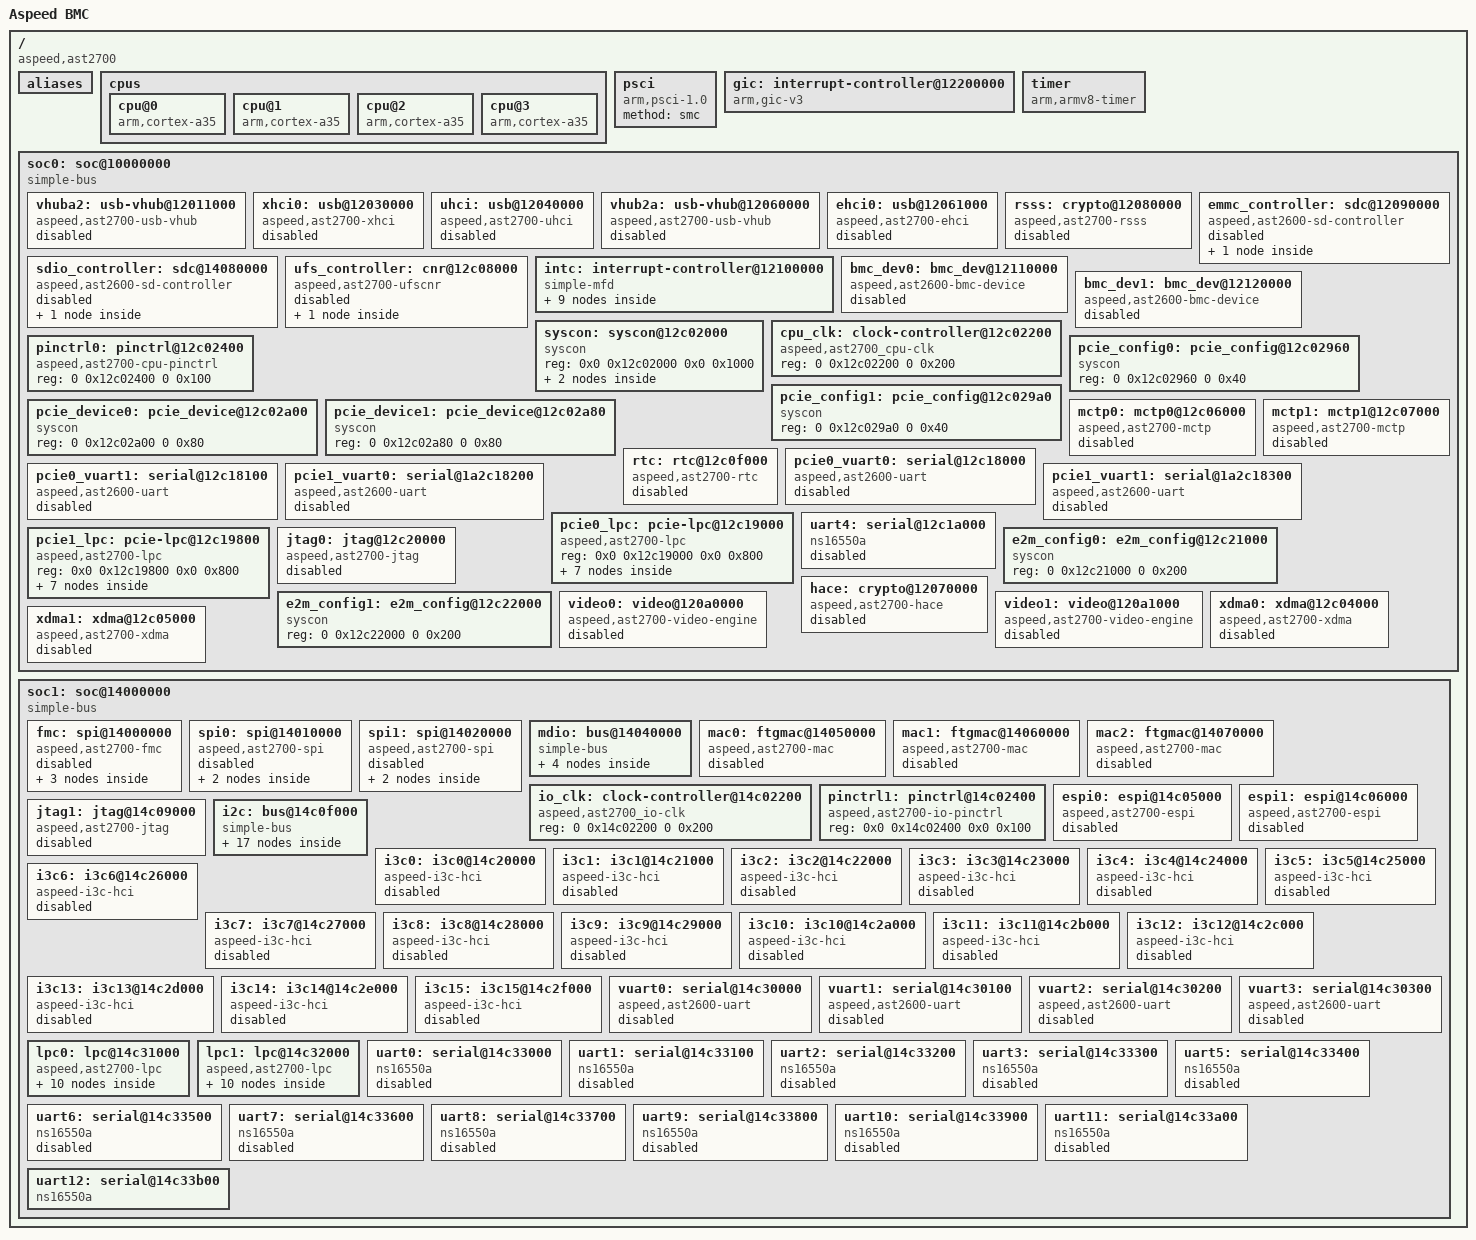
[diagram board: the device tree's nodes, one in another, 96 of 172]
// SPDX-License-Identifier: GPL-2.0-or-later
#include <dt-bindings/clock/aspeed,ast2700-clk.h>
#include <dt-bindings/reset/aspeed,ast2700-reset.h>
#include <dt-bindings/interrupt-controller/arm-gic.h>
#include <dt-bindings/interrupt-controller/aspeed-scu-ic.h>

/ {
	model = "Aspeed BMC";
	compatible = "aspeed,ast2700";
	#address-cells = <2>;
	#size-cells = <2>;
	interrupt-parent = <&gic>;

	aliases {
		serial0 = &uart0;
		serial1 = &uart1;
		serial2 = &uart2;
		serial3 = &uart3;
		serial4 = &uart4;
		serial5 = &uart5;
		serial6 = &uart6;
		serial7 = &uart7;
		serial8 = &uart8;
		serial9 = &uart9;
		serial10 = &uart10;
		serial11 = &uart11;
		serial12 = &uart12;
		serial13 = &vuart0;
		serial14 = &vuart1;
		serial15 = &vuart2;
		serial16 = &vuart3;
		serial17 = &pcie0_vuart0;
		serial18 = &pcie0_vuart1;
		serial19 = &pcie1_vuart0;
		serial20 = &pcie1_vuart1;
		i2c0 = &i2c0;
		i2c1 = &i2c1;
		i2c2 = &i2c2;
		i2c3 = &i2c3;
		i2c4 = &i2c4;
		i2c5 = &i2c5;
		i2c6 = &i2c6;
		i2c7 = &i2c7;
		i2c8 = &i2c8;
		i2c9 = &i2c9;
		i2c10 = &i2c10;
		i2c11 = &i2c11;
		i2c12 = &i2c12;
		i2c13 = &i2c13;
		i2c14 = &i2c14;
		i2c15 = &i2c15;
		mdio0 = &mdio0;
		mdio1 = &mdio1;
		mdio2 = &mdio2;
		mdio3 = &mdio3;
		video0 = &video0;
		video1 = &video1;
	};

	cpus {
		#address-cells = <1>;
		#size-cells = <0>;

		cpu@0 {
			compatible = "arm,cortex-a35";
			enable-method = "psci";
			device_type = "cpu";
			reg = <0>;
		};

		cpu@1 {
			compatible = "arm,cortex-a35";
			enable-method = "psci";
			device_type = "cpu";
			reg = <1>;
		};

		cpu@2 {
			compatible = "arm,cortex-a35";
			enable-method = "psci";
			device_type = "cpu";
			reg = <2>;
		};

		cpu@3 {
			compatible = "arm,cortex-a35";
			enable-method = "psci";
			device_type = "cpu";
			reg = <3>;
		};
	};

	psci {
		compatible = "arm,psci-1.0";
		method = "smc";
	};

	gic: interrupt-controller@12200000 {
		compatible = "arm,gic-v3";
		interrupts = <GIC_PPI 9 (GIC_CPU_MASK_SIMPLE(2) | IRQ_TYPE_LEVEL_HIGH)>;
		#interrupt-cells = <3>;
		interrupt-controller;
		interrupt-parent = <&gic>;
		#redistributor-regions = <1>;
		reg =	<0 0x12200000 0 0x10000>,		//GICD
			<0 0x12280000 0 0x80000>,		//GICR
			<0 0x40440000 0 0x1000>;		//GICC
	};

	timer {
		compatible = "arm,armv8-timer";
		interrupt-parent = <&gic>;
		interrupts = <GIC_PPI 13 (GIC_CPU_MASK_SIMPLE(2) | IRQ_TYPE_LEVEL_LOW)>,
				<GIC_PPI 14 (GIC_CPU_MASK_SIMPLE(2) | IRQ_TYPE_LEVEL_LOW)>,
				<GIC_PPI 11 (GIC_CPU_MASK_SIMPLE(2) | IRQ_TYPE_LEVEL_LOW)>,
				<GIC_PPI 10 (GIC_CPU_MASK_SIMPLE(2) | IRQ_TYPE_LEVEL_LOW)>;
		arm,cpu-registers-not-fw-configured;
		always-on;
	};

	soc0: soc@10000000 {
		compatible = "simple-bus";
		#address-cells = <2>;
		#size-cells = <2>;
		ranges;

		vhuba2: usb-vhub@12011000 {
			compatible = "aspeed,ast2700-usb-vhub";
			reg = <0x0 0x12011000 0x0 0x350>;
			interrupts = <GIC_SPI 32 IRQ_TYPE_LEVEL_HIGH>;
			clocks = <&cpu_clk AST2700_CPU_CLK_GATE_USB0CLK>;
			aspeed,vhub-downstream-ports = <7>;
			aspeed,vhub-generic-endpoints = <21>;
			status = "disabled";
		};

		xhci0: usb@12030000 {
			compatible = "aspeed,ast2700-xhci", "snps,dwc3";
			reg = <0x0 0x12030000 0x0 0x10000>;
			interrupts = <GIC_SPI 30 IRQ_TYPE_LEVEL_HIGH>;
			status = "disabled";
		};

		uhci: usb@12040000 {
			compatible = "aspeed,ast2700-uhci", "generic-uhci";
			reg = <0x0 0x12040000 0x0 0x100>;
			interrupts = <GIC_SPI 10 IRQ_TYPE_LEVEL_HIGH>;
			#ports = <2>;
			clocks = <&cpu_clk AST2700_CPU_CLK_GATE_USB0CLK>;
			status = "disabled";
		};

		vhub2a: usb-vhub@12060000 {
			compatible = "aspeed,ast2700-usb-vhub";
			reg = <0x0 0x12060000 0x0 0x350>;
			interrupts = <GIC_SPI 33 IRQ_TYPE_LEVEL_HIGH>;
			clocks = <&cpu_clk AST2700_CPU_CLK_GATE_USB0CLK>;
			aspeed,vhub-downstream-ports = <7>;
			aspeed,vhub-generic-endpoints = <21>;
			status = "disabled";
		};

		ehci0: usb@12061000 {
			compatible = "aspeed,ast2700-ehci", "generic-ehci";
			reg = <0x0 0x12061000 0x0 0x100>;
			interrupts = <GIC_SPI 33 IRQ_TYPE_LEVEL_HIGH>;
			clocks = <&cpu_clk AST2700_CPU_CLK_GATE_USB0CLK>;
			status = "disabled";
		};

		rsss: crypto@12080000 {
			compatible = "aspeed,ast2700-rsss";
			reg = <0x0 0x12080000 0 0x1000>;
			clocks = <&cpu_clk AST2700_CPU_CLK_GATE_RSACLK>;
			interrupts = <GIC_SPI 3 IRQ_TYPE_LEVEL_HIGH>;
			resets = <&cpu_clk ASPEED_RESET_RSA>,
				 <&cpu_clk ASPEED_RESET_SHA3>,
				 <&cpu_clk ASPEED_RESET_SM3>,
				 <&cpu_clk ASPEED_RESET_SM4>;
			status = "disabled";
		};

		emmc_controller: sdc@12090000 {
			compatible = "aspeed,ast2600-sd-controller";
			reg = <0 0x12090000 0 0x100>;
			#address-cells = <2>;
			#size-cells = <2>;
			ranges = <0 0 0 0x12090000 0 0x10000>;
			clocks = <&cpu_clk AST2700_CPU_CLK_GATE_EMMCCLK>;
			resets = <&cpu_clk ASPEED_RESET_EMMC>;
			status = "disable";

			emmc: sdhci@12090100 {
				compatible = "aspeed,ast2600-emmc";
				reg = <0 0x100 0 0x100>;
				sdhci,auto-cmd12;
				interrupts = <GIC_SPI 15 IRQ_TYPE_LEVEL_HIGH>;
				clocks = <&cpu_clk AST2700_CPU_CLK_GATE_EMMCCLK>;
				pinctrl-names = "default";
				pinctrl-0 = <&pinctrl_emmc_default>;
				status = "disable";
			};
		};

		sdio_controller: sdc@14080000 {
			compatible = "aspeed,ast2600-sd-controller";
			reg = <0 0x14080000 0 0x100>;
			#address-cells = <2>;
			#size-cells = <2>;
			ranges = <0 0 0 0x14080000 0 0x10000>;
			clocks = <&io_clk AST2700_IO_CLK_GATE_SDCLK>;
			resets = <&io_clk ASPEED_RESET_SD>;
			status = "disable";

			sdhci: sdhci@14080100 {
				compatible = "aspeed,ast2600-sdhci", "sdhci";
				reg = <0 0x100 0 0x100>;
				sdhci,auto-cmd12;
				interrupt-parent = <&intc5>;
				interrupts-extended = <&intc5 1>;
				clocks = <&io_clk AST2700_IO_CLK_GATE_SDCLK>;
				pinctrl-names = "default";
				pinctrl-0 = <&pinctrl_sd_default>;
				status = "disable";
			};
		};

		ufs_controller: cnr@12c08000 {
			compatible = "aspeed,ast2700-ufscnr";
			reg = <0 0x12c08000 0 0x100>;
			#address-cells = <2>;
			#size-cells = <2>;
			ranges = <0 0 0 0x12c08000 0 0x300>;
			clocks = <&cpu_clk AST2700_CPU_CLK_GATE_UFSCLK>;
			resets = <&cpu_clk ASPEED_RESET_UFS>;
			status = "disable";

			ufs: ufshc@12c08200 {
				compatible = "aspeed,ast2700-ufshc";
				reg = <0 0x200 0 0x100>;
				interrupts = <GIC_SPI 118 IRQ_TYPE_LEVEL_HIGH>;
				status = "disable";
			};
		};

		intc: interrupt-controller@12100000 {
			compatible = "simple-mfd";
			#address-cells = <2>;
			#size-cells = <2>;
			ranges = <0x0 0x0 0x0 0x12100000 0x0 0x4000>;

			intc0: interrupt-controller@1000 {
				#interrupt-cells = <1>;
				interrupt-controller;
				compatible = "aspeed,ast2700-intc-ic";
				reg = <0x0 0x1000 0x0 0x10>;
				interrupts = <GIC_SPI 128 IRQ_TYPE_LEVEL_HIGH>;
			};

			intc1: interrupt-controller@1100 {
				#interrupt-cells = <1>;
				interrupt-controller;
				compatible = "aspeed,ast2700-intc-ic";
				reg = <0x0 0x1100 0x0 0x10>;
				interrupts = <GIC_SPI 129 IRQ_TYPE_LEVEL_HIGH>;
			};

			intc2: interrupt-controller@1200 {
				#interrupt-cells = <1>;
				interrupt-controller;
				compatible = "aspeed,ast2700-intc-ic";
				reg = <0x0 0x1200 0x0 0x10>;
				interrupts = <GIC_SPI 130 IRQ_TYPE_LEVEL_HIGH>;
			};

			intc3: interrupt-controller@1300 {
				#interrupt-cells = <1>;
				interrupt-controller;
				compatible = "aspeed,ast2700-intc-ic";
				reg = <0x0 0x1300 0x0 0x10>;
				interrupts = <GIC_SPI 131 IRQ_TYPE_LEVEL_HIGH>;
			};

			intc4: interrupt-controller@1400 {
				#interrupt-cells = <1>;
				interrupt-controller;
				compatible = "aspeed,ast2700-intc-ic";
				reg = <0x0 0x1400 0x0 0x10>;
				interrupts = <GIC_SPI 132 IRQ_TYPE_LEVEL_HIGH>;
			};

			intc5: interrupt-controller@1500 {
				#interrupt-cells = <1>;
				interrupt-controller;
				compatible = "aspeed,ast2700-intc-ic";
				reg = <0x0 0x1500 0x0 0x10>;
				interrupts = <GIC_SPI 133 IRQ_TYPE_LEVEL_HIGH>;
			};

			intc6: interrupt-controller@1600 {
				#interrupt-cells = <1>;
				interrupt-controller;
				compatible = "aspeed,ast2700-intc-ic";
				reg = <0x0 0x1600 0x0 0x10>;
				interrupts = <GIC_SPI 134 IRQ_TYPE_LEVEL_HIGH>;
			};

			intc7: interrupt-controller@1700 {
				#interrupt-cells = <1>;
				interrupt-controller;
				compatible = "aspeed,ast2700-intc-ic";
				reg = <0x0 0x1700 0x0 0x10>;
				interrupts = <GIC_SPI 135 IRQ_TYPE_LEVEL_HIGH>;
			};

			intc8: interrupt-controller@1800 {
				#interrupt-cells = <1>;
				interrupt-controller;
				compatible = "aspeed,ast2700-intc-ic";
				reg = <0x0 0x12101800 0x0 0x10>;
				interrupts = <GIC_SPI 136 IRQ_TYPE_LEVEL_HIGH>;
			};
		};

		bmc_dev0: bmc_dev@12110000 {
			compatible = "aspeed,ast2600-bmc-device";
			reg = <0x0 0x12110000 0x0 0xb000>;
			interrupts = <GIC_SPI 42 IRQ_TYPE_LEVEL_HIGH>;
			aspeed,config = <&pcie_config0>;
			aspeed,device = <&pcie_device0>;
			aspeed,e2m = <&e2m_config0>;
			pcie2lpc;
			status = "disabled";
		};

		bmc_dev1: bmc_dev@12120000 {
			compatible = "aspeed,ast2600-bmc-device";
			reg = <0x0 0x12120000 0x0 0xb000>;
			interrupts = <GIC_SPI 43 IRQ_TYPE_LEVEL_HIGH>;
			aspeed,config = <&pcie_config1>;
			aspeed,device = <&pcie_device1>;
			aspeed,e2m = <&e2m_config1>;
			pcie2lpc;
			status = "disabled";
		};

		syscon: syscon@12c02000 {
			compatible = "syscon", "simple-mfd";
			reg = <0x0 0x12c02000 0x0 0x1000>;
			ranges = <0x0 0x0 0x12c02000 0x1000>;
			#address-cells = <1>;
			#size-cells = <1>;
			#clock-cells = <1>;
			#reset-cells = <1>;

			scu_ic0: interrupt-controller@1D0 {
				#interrupt-cells = <1>;
				compatible = "aspeed,ast2700-scu-ic0";
				reg = <0x1D0 0xc>;
				interrupts = <GIC_SPI 97 IRQ_TYPE_LEVEL_HIGH>;
				interrupt-controller;
			};

			scu_ic1: interrupt-controller@1E0 {
				#interrupt-cells = <1>;
				compatible = "aspeed,ast2700-scu-ic1";
				reg = <0x1E0 0xc>;
				interrupts = <GIC_SPI 98 IRQ_TYPE_LEVEL_HIGH>;
				interrupt-controller;
			};
		};

		cpu_clk: clock-controller@12c02200 {
			compatible = "aspeed,ast2700_cpu-clk";
			reg = <0 0x12c02200 0 0x200>;
			#clock-cells = <1>;
			#reset-cells = <1>;
		};

		pinctrl0: pinctrl@12c02400 {
			compatible = "aspeed,ast2700-cpu-pinctrl";
			reg = <0 0x12c02400 0 0x100>;
		};

		pcie_config0: pcie_config@12c02960 {
			compatible = "syscon", "simple-mfd";
			reg = <0 0x12c02960 0 0x40>;
		};

		pcie_config1: pcie_config@12c029a0 {
			compatible = "syscon", "simple-mfd";
			reg = <0 0x12c029a0 0 0x40>;
		};

		pcie_device0: pcie_device@12c02a00 {
			compatible = "syscon", "simple-mfd";
			reg = <0 0x12c02a00 0 0x80>;
		};

		pcie_device1: pcie_device@12c02a80 {
			compatible = "syscon", "simple-mfd";
			reg = <0 0x12c02a80 0 0x80>;
		};

		mctp0: mctp0@12c06000 {
			compatible = "aspeed,ast2700-mctp";
			reg = <0x0 0x12c06000 0x0 0x40>;
			interrupts-extended = <&gic GIC_SPI 24 IRQ_TYPE_LEVEL_HIGH>, <&scu_ic0 ASPEED_AST2700_SCU_IC0_PCIE_PERST_LO_TO_HI>;
			interrupt-names = "mctp", "pcie";
			resets = <&cpu_clk ASPEED_RESET_MCTP0>;
			aspeed,scu = <&syscon>;
			aspeed,pcieh = <&pcie_config0>;
			status = "disabled";
		};

		mctp1: mctp1@12c07000 {
			compatible = "aspeed,ast2700-mctp";
			reg = <0x0 0x12c07000 0x0 0x40>;
			interrupts-extended = <&gic GIC_SPI 25 IRQ_TYPE_LEVEL_HIGH>, <&scu_ic1 ASPEED_AST2700_SCU_IC1_PCIE_RCRST_LO_TO_HI>;
			interrupt-names = "mctp", "pcie";
			resets = <&cpu_clk ASPEED_RESET_MCTP1>;
			aspeed,scu = <&syscon>;
			aspeed,pcieh = <&pcie_config1>;
			status = "disabled";
		};

		rtc: rtc@12c0f000 {
			compatible = "aspeed,ast2700-rtc";
			reg = <0 0x12c0f000 0 0x18>;
			interrupts = <GIC_SPI 13 IRQ_TYPE_LEVEL_HIGH>;
			status = "disabled";
		};

		pcie0_vuart0: serial@12c18000 {
			compatible = "aspeed,ast2600-uart";
			reg = <0x0 0x12c18000 0x0 0x40>;
			interrupts = <GIC_SPI 80 IRQ_TYPE_LEVEL_HIGH>;
			clocks = <&cpu_clk AST2700_CPU_CLK_APB>;
			virtual;
			status = "disabled";
		};

		pcie0_vuart1: serial@12c18100 {
			compatible = "aspeed,ast2600-uart";
			reg = <0x0 0x12c18100 0x0 0x40>;
			interrupts = <GIC_SPI 81 IRQ_TYPE_LEVEL_HIGH>;
			clocks = <&cpu_clk AST2700_CPU_CLK_APB>;
			virtual;
			status = "disabled";
		};

		pcie1_vuart0: serial@1a2c18200 {
			compatible = "aspeed,ast2600-uart";
			reg = <0x0 0x12c18200 0x0 0x40>;
			interrupts = <GIC_SPI 93 IRQ_TYPE_LEVEL_HIGH>;
			clocks = <&cpu_clk AST2700_CPU_CLK_APB>;
			virtual;
			status = "disabled";
		};

		pcie1_vuart1: serial@1a2c18300 {
			compatible = "aspeed,ast2600-uart";
			interrupts = <GIC_SPI 94 IRQ_TYPE_LEVEL_HIGH>;
			clocks = <&cpu_clk AST2700_CPU_CLK_APB>;
			virtual;
			status = "disabled";
		};

		pcie0_lpc: pcie-lpc@12c19000 {
			compatible = "aspeed,ast2700-lpc", "simple-mfd", "syscon";
			reg = <0x0 0x12c19000 0x0 0x800>;

			#address-cells = <1>;
			#size-cells = <1>;
			ranges = <0x0 0x0 0x12c19000 0x800>;

			pcie0_kcs0: pcie-kcs@24 {
				compatible = "aspeed,ast2700-kcs-bmc";
				reg = <0x24 0x1>, <0x30 0x1>, <0x3c 0x1>;
				interrupts = <GIC_SPI 74 IRQ_TYPE_LEVEL_HIGH>;
				status = "disabled";
			};

			pcie0_kcs1: pcie-kcs@28 {
				compatible = "aspeed,ast2700-kcs-bmc";
				reg = <0x28 0x1>, <0x34 0x1>, <0x40 0x1>;
				interrupts = <GIC_SPI 75 IRQ_TYPE_LEVEL_HIGH>;
				status = "disabled";
			};

			pcie0_kcs2: pcie-kcs@2c {
				compatible = "aspeed,ast2700-kcs-bmc";
				reg = <0x2c 0x1>, <0x38 0x1>, <0x44 0x1>;
				interrupts = <GIC_SPI 76 IRQ_TYPE_LEVEL_HIGH>;
				status = "disabled";
			};

			pcie0_kcs3: pcie-kcs@114 {
				compatible = "aspeed,ast2700-kcs-bmc";
				reg = <0x114 0x1>, <0x118 0x1>, <0x11c 0x1>;
				interrupts = <GIC_SPI 77 IRQ_TYPE_LEVEL_HIGH>;
				status = "disabled";
			};

			pcie0_snoop: pcie-snoop@80 {
				compatible = "aspeed,ast2700-lpc-snoop";
				reg = <0x80 0x80>;
				interrupts = <GIC_SPI 71 IRQ_TYPE_LEVEL_HIGH>;
				status = "disabled";
			};

			pcie0_pcc: pcie-pcc@0 {
				compatible = "aspeed,ast2700-lpc-pcc";
				reg = <0x0 0x140>;
				interrupts = <GIC_SPI 73 IRQ_TYPE_LEVEL_HIGH>;
				status = "disabled";
			};

			pcie0_ibt: pcie_ibt@140 {
				compatible = "aspeed,ast2700-ibt-bmc";
				reg = <0x140 0x18>;
				interrupts = <GIC_SPI 72 IRQ_TYPE_LEVEL_HIGH>;
				status = "disabled";
			};

		};

		pcie1_lpc: pcie-lpc@12c19800 {
			compatible = "aspeed,ast2700-lpc", "simple-mfd", "syscon";
			reg = <0x0 0x12c19800 0x0 0x800>;

			#address-cells = <1>;
			#size-cells = <1>;
			ranges = <0x0 0x0 0x12c19800 0x800>;

			pcie1_kcs1: pcie-kcs@24 {
				compatible = "aspeed,ast2700-kcs-bmc";
				reg = <0x24 0x1>, <0x30 0x1>, <0x3c 0x1>;
				interrupts = <GIC_SPI 87 IRQ_TYPE_LEVEL_HIGH>;
				status = "disabled";
			};

			pcie1_kcs2: pcie-kcs@28 {
				compatible = "aspeed,ast2700-kcs-bmc";
				reg = <0x28 0x1>, <0x34 0x1>, <0x40 0x1>;
				interrupts = <GIC_SPI 88 IRQ_TYPE_LEVEL_HIGH>;
				kcs_chan = <7>;
				status = "disabled";
			};

			pcie1_kcs3: pcie-kcs@2c {
				compatible = "aspeed,ast2700-kcs-bmc";
				reg = <0x2c 0x1>, <0x38 0x1>, <0x44 0x1>;
				interrupts = <GIC_SPI 89 IRQ_TYPE_LEVEL_HIGH>;
				status = "disabled";
			};

			pcie1_kcs4: pcie-kcs@114 {
				compatible = "aspeed,ast2700-kcs-bmc";
				reg = <0x114 0x1>, <0x118 0x1>, <0x11c 0x1>;
				interrupts = <GIC_SPI 90 IRQ_TYPE_LEVEL_HIGH>;
				status = "disabled";
			};

			pcie1_snoop: pcie-snoop@80 {
				compatible = "aspeed,ast2700-lpc-snoop";
				reg = <0x0 0x80 0x0 0x80>;
				interrupts = <GIC_SPI 84 IRQ_TYPE_LEVEL_HIGH>;
				status = "disabled";
			};

			pcie1_pcc: pcie-pcc@0 {
				compatible = "aspeed,ast2700-lpc-pcc";
				reg = <0x0 0x0 0x0 0x140>;
				interrupts = <GIC_SPI 86 IRQ_TYPE_LEVEL_HIGH>;
				status = "disabled";
			};

			pcie1_ibt: pcie_ibt@140 {
				compatible = "aspeed,ast2700-ibt-bmc";
				reg = <0x0 0x140 0x0 0x18>;
				interrupts = <GIC_SPI 85 IRQ_TYPE_LEVEL_HIGH>;
				status = "disabled";
			};

		};

		uart4: serial@12c1a000 {
			compatible = "ns16550a";
			reg = <0x0 0x12c1a000 0x0 0x1000>;
			reg-shift = <2>;
			clocks = <&cpu_clk AST2700_CPU_CLK_GATE_UART4CLK>;
			interrupts = <GIC_SPI 8 IRQ_TYPE_LEVEL_HIGH>;
			no-loopback-test;
			status = "disabled";
		};

		jtag0: jtag@12c20000 {
			compatible = "aspeed,ast2700-jtag";
			reg= <0x0 0x12c20000 0x0 0x40>;
			interrupts = <GIC_SPI 27 IRQ_TYPE_LEVEL_HIGH>;
			clocks = <&cpu_clk AST2700_CPU_CLK_APB>;
			resets = <&cpu_clk ASPEED_RESET_JTAG0>;
			status = "disabled";
		};

		e2m_config0: e2m_config@12c21000 {
			compatible = "syscon", "simple-mfd";
			reg = <0 0x12c21000 0 0x200>;
		};

		e2m_config1: e2m_config@12c22000 {
			compatible = "syscon", "simple-mfd";
			reg = <0 0x12c22000 0 0x200>;
		};

		hace: crypto@12070000 {
			compatible = "aspeed,ast2700-hace";
			reg = <0x0 0x12070000 0x0 0x200>;
			interrupts = <GIC_SPI 4 IRQ_TYPE_LEVEL_HIGH>;
			clocks = <&cpu_clk AST2700_CPU_CLK_GATE_YCLK>;
			resets = <&cpu_clk ASPEED_RESET_HACE>;
			status = "disabled";
		};

		video0: video@120a0000 {
			compatible = "aspeed,ast2700-video-engine";
			reg = <0x0 0x120a0000 0x0 0x1000>;
			clocks = <&cpu_clk AST2700_CPU_CLK_GATE_VCLK>,
				 <&cpu_clk AST2700_CPU_CLK_GATE_ECLK>;
			clock-names = "vclk", "eclk";
			interrupts = <GIC_SPI 7 IRQ_TYPE_LEVEL_HIGH>;
			resets = <&cpu_clk ASPEED_RESET_VIDEO>;
			aspeed,scu = <&syscon>;
			status = "disabled";
		};

		video1: video@120a1000 {
			compatible = "aspeed,ast2700-video-engine";
			reg = <0x0 0x120a1000 0x0 0x1000>;
			clocks = <&cpu_clk AST2700_CPU_CLK_GATE_VCLK>,
				 <&cpu_clk AST2700_CPU_CLK_GATE_ECLK>;
			clock-names = "vclk", "eclk";
			interrupts = <GIC_SPI 114 IRQ_TYPE_LEVEL_HIGH>;
			resets = <&cpu_clk ASPEED_RESET_VIDEO>;
			aspeed,scu = <&syscon>;
			status = "disabled";
		};

		xdma0: xdma@12c04000 {
			compatible = "aspeed,ast2700-xdma";
			reg = <0x0 0x12c04000 0x0 0x100>;
			clocks = <&cpu_clk AST2700_CPU_CLK_GATE_BCLK>;
			resets = <&cpu_clk ASPEED_RESET_XDMA0>;
			reset-names = "device";
			interrupts-extended = <&gic GIC_SPI 5 IRQ_TYPE_LEVEL_HIGH>,
					      <&scu_ic0 ASPEED_AST2700_SCU_IC0_PCIE_PERST_LO_TO_HI>;
			aspeed,pcie-device = "bmc";
			aspeed,scu = <&syscon>;
			status = "disabled";
		};

		xdma1: xdma@12c05000 {
			compatible = "aspeed,ast2700-xdma";
			reg = <0x0 0x12c05000 0x0 0x100>;
			clocks = <&cpu_clk AST2700_CPU_CLK_GATE_BCLK>;
			resets = <&cpu_clk ASPEED_RESET_XDMA1>;
			reset-names = "device";
			interrupts-extended = <&gic GIC_SPI 6 IRQ_TYPE_LEVEL_HIGH>,
					      <&scu_ic1 ASPEED_AST2700_SCU_IC1_PCIE_RCRST_LO_TO_HI>;
			aspeed,pcie-device = "bmc";
			aspeed,scu = <&syscon>;
			status = "disabled";
		};
	};

	soc1: soc@14000000 {
		compatible = "simple-bus";
		#address-cells = <2>;
		#size-cells = <2>;
		ranges;

		fmc: spi@14000000 {
			reg = <0x0 0x14000000 0x0 0xc4>, <0x1 0x00000000 0x0 0x80000000>;
			#address-cells = <1>;
			#size-cells = <0>;
			compatible = "aspeed,ast2700-fmc";
			status = "disabled";
			clocks = <&io_clk AST2700_IO_CLK_AHB>;
			num-cs = <3>;

			flash@0 {
				reg = < 0 >;
				compatible = "jedec,spi-nor";
				spi-max-frequency = <50000000>;
				spi-rx-bus-width = <2>;
				status = "disabled";
			};

			flash@1 {
				reg = < 1 >;
				compatible = "jedec,spi-nor";
				spi-max-frequency = <50000000>;
				spi-rx-bus-width = <2>;
				status = "disabled";
			};

			flash@2 {
				reg = < 2 >;
				compatible = "jedec,spi-nor";
				spi-max-frequency = <50000000>;
				spi-rx-bus-width = <2>;
				status = "disabled";
			};
		};

		spi0: spi@14010000 {
			reg = <0x0 0x14010000 0x0 0xc4>, <0x1 0x80000000 0x0 0x80000000>;
			#address-cells = <1>;
			#size-cells = <0>;
			compatible = "aspeed,ast2700-spi";
			clocks = <&io_clk AST2700_IO_CLK_AHB>;
			status = "disabled";
			num-cs = <2>;

			flash@0 {
				reg = < 0 >;
				compatible = "jedec,spi-nor";
				spi-max-frequency = <50000000>;
				spi-rx-bus-width = <2>;
				status = "disabled";
			};

			flash@1 {
				reg = < 1 >;
				compatible = "jedec,spi-nor";
				spi-max-frequency = <50000000>;
				spi-rx-bus-width = <2>;
				status = "disabled";
			};
		};

		spi1: spi@14020000 {
			reg = <0x0 0x14020000 0x0 0xc4>, <0x2 0x00000000 0x0 0x80000000>;
			#address-cells = <1>;
			#size-cells = <0>;
			compatible = "aspeed,ast2700-spi";
			clocks = <&io_clk AST2700_IO_CLK_AHB>;
			status = "disabled";
			num-cs = <3>;

			flash@0 {
				reg = < 0 >;
				compatible = "jedec,spi-nor";
				spi-max-frequency = <50000000>;
				spi-rx-bus-width = <2>;
				status = "disabled";
			};

			flash@1 {
				reg = < 1 >;
				compatible = "jedec,spi-nor";
				spi-max-frequency = <50000000>;
				spi-rx-bus-width = <2>;
				status = "disabled";
			};
		};

		mdio: bus@14040000 {
			compatible = "simple-bus";
			#address-cells = <2>;
			#size-cells = <2>;
			ranges = <0 0 0 0x14040000 0 0x100>;

			mdio0: mdio@0 {
				compatible = "aspeed,ast2700-mdio";
				reg = <0 0 0 0x8>;
				resets = <&io_clk ASPEED_RESET_MII>;
				status = "disabled";
			};

			mdio1: mdio@8 {
				compatible = "aspeed,ast2700-mdio";
				reg = <0 0x8 0 0x8>;
				resets = <&io_clk ASPEED_RESET_MII>;
				status = "disabled";
			};

			mdio2: mdio@10 {
				compatible = "aspeed,ast2700-mdio";
				reg = <0 0x10 0 0x8>;
				resets = <&io_clk ASPEED_RESET_MII>;
				status = "disabled";
			};

			mdio3: mdio@18 {
				compatible = "aspeed,ast2700-mdio";
				reg = <0 0x18 0 0x8>;
				resets = <&io_clk ASPEED_RESET_MII>;
				status = "disabled";
			};
		};

		mac0: ftgmac@14050000 {
			compatible = "aspeed,ast2700-mac", "faraday,ftgmac100";
			reg = <0x0 0x14050000 0x0 0x200>;
			interrupt-parent = <&intc4>;
			interrupts-extended = <&intc4 0>;

			clocks = <&io_clk AST2700_IO_CLK_GATE_MAC0CLK>;
			resets = <&io_clk ASPEED_RESET_MAC0>;
			status = "disabled";
		};

		mac1: ftgmac@14060000 {
			compatible = "aspeed,ast2700-mac", "faraday,ftgmac100";
			reg = <0x0 0x14060000 0x0 0x200>;
			interrupt-parent = <&intc4>;
			interrupts-extended = <&intc4 1>;

			clocks = <&io_clk AST2700_IO_CLK_GATE_MAC1CLK>;
			resets = <&io_clk ASPEED_RESET_MAC1>;
			status = "disabled";
		};

		mac2: ftgmac@14070000 {
			compatible = "aspeed,ast2700-mac", "faraday,ftgmac100";
			reg = <0x0 0x14070000 0x0 0x200>;
			interrupt-parent = <&intc4>;
			interrupts-extended = <&intc4 2>;

			clocks = <&io_clk AST2700_IO_CLK_GATE_MAC2CLK>;
			resets = <&io_clk ASPEED_RESET_MAC2>;
			status = "disabled";
		};

		io_clk: clock-controller@14c02200 {
			compatible = "aspeed,ast2700_io-clk";
			reg = <0 0x14c02200 0 0x200>;
			#clock-cells = <1>;
			#reset-cells = <1>;
		};

		pinctrl1: pinctrl@14c02400 {
			compatible = "aspeed,ast2700-io-pinctrl";
			reg = <0x0 0x14c02400 0x0 0x100>;
		};

		espi0: espi@14c05000 {
			compatible = "aspeed,ast2700-espi";
			reg = <0 0x14c05000 0 0x1000>;
			interrupts-extended = <&intc0 10>, <&intc0 16>;
			clocks = <&io_clk AST2700_IO_CLK_GATE_ESPI0CLK>;
			resets = <&io_clk ASPEED_RESET_ESPI0>;
			pinctrl-names = "default";
			pinctrl-1 = <&pinctrl_espi0_default>;
			status = "disabled";
		};

		espi1: espi@14c06000 {
			compatible = "aspeed,ast2700-espi";
			reg = <0 0x14c06000 0 0x1000>;
			interrupts-extended = <&intc1 10>, <&intc1 16>;
			clocks = <&io_clk AST2700_IO_CLK_GATE_ESPI1CLK>;
			resets = <&io_clk ASPEED_RESET_ESPI1>;
			pinctrl-names = "default";
			pinctrl-1 = <&pinctrl_espi1_default>;
			status = "disabled";
		};

		jtag1: jtag@14c09000 {
			compatible = "aspeed,ast2700-jtag";
			reg= <0x0 0x14c09000 0x0 0x40>;
			interrupts-extended = <&intc5 2>;
			clocks = <&io_clk AST2700_IO_CLK_AHB>;
			resets = <&io_clk ASPEED_RESET_JTAG1>;
			status = "disabled";
		};

		i2c: bus@14c0f000 {
			compatible = "simple-bus";
			#address-cells = <1>;
			#size-cells = <1>;
			ranges = <0x0 0x0 0x14c0f000 0x1100>;
		};

		i3c0: i3c0@14c20000 {
			compatible = "aspeed-i3c-hci";
			#address-cells = <1>;
			#size-cells = <0>;
			reg = <0x0 0x14c20000 0x0 0x1000>;
			interrupts-extended = <&intc3 0>;
			clocks = <&io_clk AST2700_IO_CLK_GATE_I3C0CLK>;
			resets = <&io_clk ASPEED_RESET_I3C0>;
			status = "disabled";
		};

		i3c1: i3c1@14c21000 {
			compatible = "aspeed-i3c-hci";
			#address-cells = <1>;
			#size-cells = <0>;
			reg = <0x0 0x14c21000 0x0 0x1000>;
			interrupts-extended = <&intc3 1>;
			clocks = <&io_clk AST2700_IO_CLK_GATE_I3C1CLK>;
			resets = <&io_clk ASPEED_RESET_I3C1>;
			status = "disabled";
		};

		i3c2: i3c2@14c22000 {
			compatible = "aspeed-i3c-hci";
			#address-cells = <1>;
			#size-cells = <0>;
			reg = <0x0 0x14c22000 0x0 0x1000>;
			interrupts-extended = <&intc3 2>;
			clocks = <&io_clk AST2700_IO_CLK_GATE_I3C2CLK>;
			resets = <&io_clk ASPEED_RESET_I3C2>;
			status = "disabled";
		};

		i3c3: i3c3@14c23000 {
			compatible = "aspeed-i3c-hci";
			#address-cells = <1>;
			#size-cells = <0>;
			reg = <0x0 0x14c23000 0x0 0x1000>;
			interrupts-extended = <&intc3 3>;
			clocks = <&io_clk AST2700_IO_CLK_GATE_I3C3CLK>;
			resets = <&io_clk ASPEED_RESET_I3C3>;
			status = "disabled";
		};

		i3c4: i3c4@14c24000 {
			compatible = "aspeed-i3c-hci";
			#address-cells = <1>;
			#size-cells = <0>;
			reg = <0x0 0x14c24000 0x0 0x1000>;
			interrupts-extended = <&intc3 4>;
			clocks = <&io_clk AST2700_IO_CLK_GATE_I3C4CLK>;
			resets = <&io_clk ASPEED_RESET_I3C4>;
			status = "disabled";
		};

		i3c5: i3c5@14c25000 {
			compatible = "aspeed-i3c-hci";
			#address-cells = <1>;
			#size-cells = <0>;
			reg = <0x0 0x14c25000 0x0 0x1000>;
			interrupts-extended = <&intc3 5>;
			clocks = <&io_clk AST2700_IO_CLK_GATE_I3C5CLK>;
			resets = <&io_clk ASPEED_RESET_I3C5>;
			status = "disabled";
		};

		i3c6: i3c6@14c26000 {
			compatible = "aspeed-i3c-hci";
			#address-cells = <1>;
			#size-cells = <0>;
			reg = <0x0 0x14c26000 0x0 0x1000>;
			interrupts-extended = <&intc3 6>;
			clocks = <&io_clk AST2700_IO_CLK_GATE_I3C6CLK>;
			resets = <&io_clk ASPEED_RESET_I3C6>;
			status = "disabled";
		};

		i3c7: i3c7@14c27000 {
			compatible = "aspeed-i3c-hci";
			#address-cells = <1>;
			#size-cells = <0>;
			reg = <0x0 0x14c27000 0x0 0x1000>;
			interrupts-extended = <&intc3 7>;
			clocks = <&io_clk AST2700_IO_CLK_GATE_I3C7CLK>;
			resets = <&io_clk ASPEED_RESET_I3C7>;
			status = "disabled";
		};

		i3c8: i3c8@14c28000 {
			compatible = "aspeed-i3c-hci";
			#address-cells = <1>;
			#size-cells = <0>;
			reg = <0x0 0x14c28000 0x0 0x1000>;
			interrupts-extended = <&intc3 8>;
			clocks = <&io_clk AST2700_IO_CLK_GATE_I3C8CLK>;
			resets = <&io_clk ASPEED_RESET_I3C8>;
			status = "disabled";
		};

		i3c9: i3c9@14c29000 {
			compatible = "aspeed-i3c-hci";
			#address-cells = <1>;
			#size-cells = <0>;
			reg = <0x0 0x14c29000 0x0 0x1000>;
			interrupts-extended = <&intc3 9>;
			clocks = <&io_clk AST2700_IO_CLK_GATE_I3C9CLK>;
			resets = <&io_clk ASPEED_RESET_I3C9>;
			status = "disabled";
		};

		i3c10: i3c10@14c2a000 {
			compatible = "aspeed-i3c-hci";
			#address-cells = <1>;
			#size-cells = <0>;
			reg = <0x0 0x14c2a000 0x0 0x1000>;
			interrupts-extended = <&intc3 10>;
			clocks = <&io_clk AST2700_IO_CLK_GATE_I3C10CLK>;
			resets = <&io_clk ASPEED_RESET_I3C10>;
			status = "disabled";
		};

		i3c11: i3c11@14c2b000 {
			compatible = "aspeed-i3c-hci";
			#address-cells = <1>;
			#size-cells = <0>;
			reg = <0x0 0x14c2b000 0x0 0x1000>;
			interrupts-extended = <&intc3 11>;
			clocks = <&io_clk AST2700_IO_CLK_GATE_I3C11CLK>;
			resets = <&io_clk ASPEED_RESET_I3C11>;
			status = "disabled";
		};

		i3c12: i3c12@14c2c000 {
			compatible = "aspeed-i3c-hci";
			#address-cells = <1>;
			#size-cells = <0>;
			reg = <0x0 0x14c2c000 0x0 0x1000>;
			interrupts-extended = <&intc3 12>;
			clocks = <&io_clk AST2700_IO_CLK_GATE_I3C12CLK>;
			resets = <&io_clk ASPEED_RESET_I3C12>;
			status = "disabled";
		};

		i3c13: i3c13@14c2d000 {
			compatible = "aspeed-i3c-hci";
			#address-cells = <1>;
			#size-cells = <0>;
			reg = <0x0 0x14c2d000 0x0 0x1000>;
			interrupts-extended = <&intc3 13>;
			clocks = <&io_clk AST2700_IO_CLK_GATE_I3C13CLK>;
			resets = <&io_clk ASPEED_RESET_I3C13>;
			status = "disabled";
		};

		i3c14: i3c14@14c2e000 {
			compatible = "aspeed-i3c-hci";
			#address-cells = <1>;
			#size-cells = <0>;
			reg = <0x0 0x14c2e000 0x0 0x1000>;
			interrupts-extended = <&intc3 14>;
			clocks = <&io_clk AST2700_IO_CLK_GATE_I3C14CLK>;
			resets = <&io_clk ASPEED_RESET_I3C14>;
			status = "disabled";
		};

		i3c15: i3c15@14c2f000 {
			compatible = "aspeed-i3c-hci";
			#address-cells = <1>;
			#size-cells = <0>;
			reg = <0x0 0x14c2f000 0x0 0x1000>;
			interrupts-extended = <&intc3 15>;
			clocks = <&io_clk AST2700_IO_CLK_GATE_I3C15CLK>;
			resets = <&io_clk ASPEED_RESET_I3C15>;
			status = "disabled";
		};

		vuart0: serial@14c30000 {
			compatible = "aspeed,ast2600-uart";
			reg = <0x0 0x14c30000 0x0 0x40>;
			interrupts-extended = <&intc0 17>;
			clock-frequency = <1846154>;
			virtual;
			status = "disabled";
		};

		vuart1: serial@14c30100 {
			compatible = "aspeed,ast2600-uart";
			reg = <0x0 0x14c30100 0x0 0x40>;
			interrupts-extended = <&intc0 18>;
			clock-frequency = <1846154>;
			virtual;
			status = "disabled";
		};

		vuart2: serial@14c30200 {
			compatible = "aspeed,ast2600-uart";
			reg = <0x0 0x14c30200 0x0 0x40>;
			interrupts-extended = <&intc1 17>;
			clock-frequency = <1846154>;
			virtual;
			status = "disabled";
		};

		vuart3: serial@14c30300 {
			compatible = "aspeed,ast2600-uart";
			reg = <0x0 0x14c30300 0x0 0x40>;
			interrupts-extended = <&intc1 18>;
			clock-frequency = <1846154>;
			virtual;
			status = "disabled";
		};

		lpc0: lpc@14c31000 {
			compatible = "aspeed,ast2700-lpc", "simple-mfd", "syscon";
			reg = <0x0 0x14c31000 0x0 0x1000>;
			reg-io-width = <4>;

			#address-cells = <1>;
			#size-cells = <1>;
			ranges = <0x0 0x0 0x14c31000 0x1000>;

			lpc0_kcs0: lpc_kcs@24 {
				compatible = "aspeed,ast2700-kcs-bmc";
				reg = <0x24 0x1>, <0x30 0x1>, <0x3c 0x1>;
				interrupts-extended = <&intc0 4>;
				status = "disabled";
			};

			lpc0_kcs1: lpc_kcs@28 {
				compatible = "aspeed,ast2700-kcs-bmc";
				reg = <0x28 0x1>, <0x34 0x1>, <0x40 0x1>;
				interrupts-extended = <&intc0 5>;
				status = "disabled";
			};

			lpc0_kcs2: lpc_kcs@2c {
				compatible = "aspeed,ast2700-kcs-bmc";
				reg = <0x2c 0x1>, <0x38 0x1>, <0x44 0x1>;
				interrupts-extended = <&intc0 6>;
				status = "disabled";
			};

			lpc0_kcs3: lpc_kcs@114 {
				compatible = "aspeed,ast2700-kcs-bmc";
				reg = <0x114 0x1>, <0x118 0x1>, <0x11c 0x1>;
				interrupts-extended = <&intc0 7>;
				status = "disabled";
			};

			lpc0_snoop: lpc-snoop@80 {
				compatible = "aspeed,ast2600-lpc-snoop";
				reg = <0x80 0x80>;
				interrupts-extended = <&intc0 1>;
				status = "disabled";
			};

			lpc0_pcc: lpc-pcc@0 {
				compatible = "aspeed,ast2600-lpc-pcc";
				reg = <0x0 0x140>;
				interrupts-extended = <&intc0 3>;
				status = "disabled";
			};

			lpc0_reset: reset-controller@98 {
				compatible = "aspeed,ast2700-lpc-reset";
				reg = <0x98 0x4>;
				#reset-cells = <1>;
			};

			lpc0_uart_routing: uart-routing@98 {
				compatible = "aspeed,ast2700n0-uart-routing";
				reg = <0x98 0x8>;
				status = "disabled";
			};

			lpc0_ibt: ibt@140 {
				compatible = "aspeed,ast2700-ibt-bmc";
				reg = <0x140 0x18>;
				interrupts-extended = <&intc0 2>;
				status = "disabled";
			};

			lpc0_mbox: mbox@200 {
				compatible = "aspeed,ast2700-mbox";
				reg = <0x200 0xc0>;
				interrupts-extended = <&intc0 20>;
				status = "disabled";
			};
		};

		lpc1: lpc@14c32000 {
			compatible = "aspeed,ast2700-lpc", "simple-mfd", "syscon";
			reg = <0x0 0x14c32000 0x0 0x1000>;
			reg-io-width = <4>;

			#address-cells = <1>;
			#size-cells = <1>;
			ranges = <0x0 0x0 0x14c32000 0x1000>;

			lpc1_kcs0: kcs@24 {
				compatible = "aspeed,ast2700-kcs-bmc";
				reg = <0x24 0x1>, <0x30 0x1>, <0x3c 0x1>;
				interrupts-extended = <&intc1 4>;
				status = "disabled";
			};

			lpc1_kcs1: kcs@28 {
				compatible = "aspeed,ast2700-kcs-bmc";
				reg = <0x28 0x1>, <0x34 0x1>, <0x40 0x1>;
				interrupts-extended = <&intc1 5>;
				status = "disabled";
			};

			lpc1_kcs2: kcs@2c {
				compatible = "aspeed,ast2700-kcs-bmc";
				reg = <0x2c 0x1>, <0x38 0x1>, <0x44 0x1>;
				interrupts-extended = <&intc1 6>;
				status = "disabled";
			};

			lpc1_kcs3: kcs@114 {
				compatible = "aspeed,ast2700-kcs-bmc";
				reg = <0x114 0x1>, <0x118 0x1>, <0x11c 0x1>;
				interrupts-extended = <&intc1 7>;
				status = "disabled";
			};

			lpc1_snoop: lpc-snoop@80 {
				compatible = "aspeed,ast2700-lpc-snoop";
				reg = <0x80 0x80>;
				interrupts-extended = <&intc1 1>;
				status = "disabled";
			};

			lpc1_pcc: lpc-pcc@0 {
				compatible = "aspeed,ast2700-lpc-pcc";
				reg = <0x0 0x140>;
				interrupts-extended = <&intc1 3>;
				status = "disabled";
			};

			lpc1_reset: reset-controller@98 {
				compatible = "aspeed,ast2700-lpc-reset";
				reg = <0x98 0x4>;
				#reset-cells = <1>;
			};

			lpc1_uart_routing: uart-routing@98 {
				compatible = "aspeed,ast2700n1-uart-routing";
				reg = <0x98 0x8>;
				status = "disabled";
			};

			lpc1_ibt: ibt@140 {
				compatible = "aspeed,ast2700-ibt-bmc";
				reg = <0x140 0x18>;
				interrupts-extended = <&intc1 2>;
				status = "disabled";
			};

			lpc1_mbox: mbox@200 {
				compatible = "aspeed,ast2700-mbox";
				reg = <0x200 0xc0>;
				interrupts-extended = <&intc1 20>;
				status = "disabled";
			};
		};

		uart0: serial@14c33000 {
			compatible = "ns16550a";
			reg = <0x0 0x14c33000 0x0 0x20>;
			reg-shift = <2>;
			reg-io-width = <4>;
			clocks = <&io_clk AST2700_IO_CLK_GATE_UART0CLK>;
			interrupts-extended = <&intc4 7>;
			no-loopback-test;
			pinctrl-names = "default";
			status = "disabled";
		};

		uart1: serial@14c33100 {
			compatible = "ns16550a";
			reg = <0x0 0x14c33100 0x0 0x20>;
			reg-shift = <2>;
			reg-io-width = <4>;
			clocks = <&io_clk AST2700_IO_CLK_GATE_UART1CLK>;
			interrupts-extended = <&intc4 8>;
			no-loopback-test;
			pinctrl-names = "default";
			status = "disabled";
		};

		uart2: serial@14c33200 {
			compatible = "ns16550a";
			reg = <0x0 0x14c33200 0x0 0x20>;
			reg-shift = <2>;
			reg-io-width = <4>;
			clocks = <&io_clk AST2700_IO_CLK_GATE_UART2CLK>;
			interrupts-extended = <&intc4 9>;
			no-loopback-test;
			pinctrl-names = "default";
			status = "disabled";
		};

		uart3: serial@14c33300 {
			compatible = "ns16550a";
			reg = <0x0 0x14c33300 0x0 0x20>;
			reg-shift = <2>;
			reg-io-width = <4>;
			clocks = <&io_clk AST2700_IO_CLK_GATE_UART3CLK>;
			interrupts-extended = <&intc4 10>;
			no-loopback-test;
			pinctrl-names = "default";
			status = "disabled";
		};

		uart5: serial@14c33400 {
			compatible = "ns16550a";
			reg = <0x0 0x14c33400 0x0 0x20>;
			reg-shift = <2>;
			reg-io-width = <4>;
			clocks = <&io_clk AST2700_IO_CLK_GATE_UART5CLK>;
			interrupts-extended = <&intc4 11>;
			no-loopback-test;
			pinctrl-names = "default";
			status = "disabled";
		};

		uart6: serial@14c33500 {
			compatible = "ns16550a";
			reg = <0x0 0x14c33500 0x0 0x20>;
			reg-shift = <2>;
			reg-io-width = <4>;
			clocks = <&io_clk AST2700_IO_CLK_GATE_UART6CLK>;
			interrupts-extended = <&intc4 12>;
			no-loopback-test;
			pinctrl-names = "default";
			status = "disabled";
		};

		uart7: serial@14c33600 {
			compatible = "ns16550a";
			reg = <0x0 0x14c33600 0x0 0x20>;
			reg-shift = <2>;
			reg-io-width = <4>;
			clocks = <&io_clk AST2700_IO_CLK_GATE_UART7CLK>;
			interrupts-extended = <&intc4 13>;
			no-loopback-test;
			pinctrl-names = "default";
			status = "disabled";
		};

		uart8: serial@14c33700 {
			compatible = "ns16550a";
			reg = <0x0 0x14c33700 0x0 0x20>;
			reg-shift = <2>;
			reg-io-width = <4>;
			clocks = <&io_clk AST2700_IO_CLK_GATE_UART8CLK>;
			interrupts-extended = <&intc4 14>;
			no-loopback-test;
			pinctrl-names = "default";
			status = "disabled";
		};

		uart9: serial@14c33800 {
			compatible = "ns16550a";
			reg = <0x0 0x14c33800 0x0 0x20>;
			reg-shift = <2>;
			reg-io-width = <4>;
			clocks = <&io_clk AST2700_IO_CLK_GATE_UART9CLK>;
			interrupts-extended = <&intc4 15>;
			no-loopback-test;
			pinctrl-names = "default";
			status = "disabled";
		};

		uart10: serial@14c33900 {
			compatible = "ns16550a";
			reg = <0x0 0x14c33900 0x0 0x20>;
			reg-shift = <2>;
			reg-io-width = <4>;
			clocks = <&io_clk AST2700_IO_CLK_GATE_UART10CLK>;
			interrupts-extended = <&intc4 16>;
			no-loopback-test;
			pinctrl-names = "default";
			status = "disabled";
		};

		uart11: serial@14c33a00 {
			compatible = "ns16550a";
			reg = <0x0 0x14c33a00 0x0 0x20>;
			reg-shift = <2>;
			reg-io-width = <4>;
			clocks = <&io_clk AST2700_IO_CLK_GATE_UART11CLK>;
			interrupts-extended = <&intc4 17>;
			no-loopback-test;
			pinctrl-names = "default";
			status = "disabled";
		};

		uart12: serial@14c33b00 {
			compatible = "ns16550a";
			reg = <0x0 0x14c33b00 0x0 0x20>;
			reg-shift = <2>;
			reg-io-width = <4>;
			clocks = <&io_clk AST2700_IO_CLK_GATE_UART12CLK>;
			interrupts-extended = <&intc4 18>;
			no-loopback-test;
			pinctrl-names = "default";
			status = "okay";
		};
	};
};

#include "aspeed-g7-pinctrl.dtsi"

&i2c {
	i2c_global: i2c-global-regs@0 {
		compatible = "aspeed,i2c-global", "simple-mfd", "syscon";
		reg = <0x0 0x100>;
	};

	i2c0: i2c-bus@100 {
		#address-cells = <1>;
		#size-cells = <0>;
		#interrupt-cells = <1>;
		reg = <0x100 0x80>, <0x1A0 0x20>;
		compatible = "aspeed,ast2600-i2cv2";
		aspeed,global-regs = <&i2c_global>;
		aspeed,enable-dma;
		clocks = <&io_clk AST2700_IO_CLK_APB>;
		resets = <&io_clk ASPEED_RESET_I2C>;
		interrupts-extended = <&intc2 0>;
		clock-frequency = <100000>;
		pinctrl-names = "default";
		pinctrl-0 = <&pinctrl_i2c0_default>;
		status = "disabled";
	};

	i2c1: i2c-bus@200 {
		#address-cells = <1>;
		#size-cells = <0>;
		#interrupt-cells = <1>;
		reg = <0x200 0x80>, <0x2A0 0x20>;
		compatible = "aspeed,ast2600-i2cv2";
		aspeed,global-regs = <&i2c_global>;
		aspeed,enable-dma;
		clocks = <&io_clk AST2700_IO_CLK_APB>;
		resets = <&io_clk ASPEED_RESET_I2C>;
		interrupts-extended = <&intc2 1>;
		clock-frequency = <100000>;
		pinctrl-names = "default";
		pinctrl-0 = <&pinctrl_i2c1_default>;
		status = "disabled";
	};

	i2c2: i2c-bus@300 {
		#address-cells = <1>;
		#size-cells = <0>;
		#interrupt-cells = <1>;
		reg = <0x300 0x80>, <0x3A0 0x20>;
		compatible = "aspeed,ast2600-i2cv2";
		aspeed,global-regs = <&i2c_global>;
		aspeed,enable-dma;
		clocks = <&io_clk AST2700_IO_CLK_APB>;
		resets = <&io_clk ASPEED_RESET_I2C>;
		interrupts-extended = <&intc2 2>;
		clock-frequency = <100000>;
		pinctrl-names = "default";
		pinctrl-0 = <&pinctrl_i2c2_default>;
		status = "disabled";
	};

	i2c3: i2c-bus@400 {
		#address-cells = <1>;
		#size-cells = <0>;
		#interrupt-cells = <1>;
		reg = <0x400 0x80>, <0x4A0 0x20>;
		compatible = "aspeed,ast2600-i2cv2";
		aspeed,global-regs = <&i2c_global>;
		clocks = <&io_clk AST2700_IO_CLK_APB>;
		resets = <&io_clk ASPEED_RESET_I2C>;
		interrupts-extended = <&intc2 3>;
		clock-frequency = <100000>;
		pinctrl-names = "default";
		pinctrl-0 = <&pinctrl_i2c3_default>;
		status = "disabled";
	};

	i2c4: i2c-bus@500 {
		#address-cells = <1>;
		#size-cells = <0>;
		#interrupt-cells = <1>;
		reg = <0x500 0x80>, <0x5A0 0x20>;
		compatible = "aspeed,ast2600-i2cv2";
		aspeed,global-regs = <&i2c_global>;
		aspeed,enable-dma;
		clocks = <&io_clk AST2700_IO_CLK_APB>;
		resets = <&io_clk ASPEED_RESET_I2C>;
		clock-frequency = <100000>;
		interrupts-extended = <&intc2 4>;
		pinctrl-names = "default";
		pinctrl-0 = <&pinctrl_i2c4_default>;
		status = "disabled";
	};

	i2c5: i2c-bus@600 {
		#address-cells = <1>;
		#size-cells = <0>;
		#interrupt-cells = <1>;
		reg = <0x600 0x80>, <0x6A0 0x20>;
		compatible = "aspeed,ast2600-i2cv2";
		aspeed,global-regs = <&i2c_global>;
		aspeed,enable-dma;
		clocks = <&io_clk AST2700_IO_CLK_APB>;
		resets = <&io_clk ASPEED_RESET_I2C>;
		interrupts-extended = <&intc2 5>;
		clock-frequency = <100000>;
		pinctrl-names = "default";
		pinctrl-0 = <&pinctrl_i2c5_default>;
		status = "disabled";
	};

	i2c6: i2c-bus@700 {
		#address-cells = <1>;
		#size-cells = <0>;
		#interrupt-cells = <1>;
		reg = <0x700 0x80>, <0x7A0 0x20>;
		compatible = "aspeed,ast2600-i2cv2";
		aspeed,global-regs = <&i2c_global>;
		aspeed,enable-dma;
		clocks = <&io_clk AST2700_IO_CLK_APB>;
		resets = <&io_clk ASPEED_RESET_I2C>;
		interrupts-extended = <&intc2 6>;
		clock-frequency = <100000>;
		pinctrl-names = "default";
		pinctrl-0 = <&pinctrl_i2c6_default>;
		status = "disabled";
	};

	i2c7: i2c-bus@800 {
		#address-cells = <1>;
		#size-cells = <0>;
		#interrupt-cells = <1>;
		reg = <0x800 0x80>, <0x8A0 0x20>;
		compatible = "aspeed,ast2600-i2cv2";
		aspeed,global-regs = <&i2c_global>;
		aspeed,enable-dma;
		clocks = <&io_clk AST2700_IO_CLK_APB>;
		resets = <&io_clk ASPEED_RESET_I2C>;
		interrupts-extended = <&intc2 7>;
		clock-frequency = <100000>;
		pinctrl-names = "default";
		pinctrl-0 = <&pinctrl_i2c7_default>;
		status = "disabled";
	};

	i2c8: i2c-bus@900 {
		#address-cells = <1>;
		#size-cells = <0>;
		#interrupt-cells = <1>;
		reg = <0x900 0x80>, <0x9A0 0x20>;
		compatible = "aspeed,ast2600-i2cv2";
		aspeed,global-regs = <&i2c_global>;
		aspeed,enable-dma;
		clocks = <&io_clk AST2700_IO_CLK_APB>;
		resets = <&io_clk ASPEED_RESET_I2C>;
		interrupts-extended = <&intc2 8>;
		clock-frequency = <100000>;
		pinctrl-names = "default";
		pinctrl-0 = <&pinctrl_i2c8_default>;
		status = "disabled";
	};

	i2c9: i2c-bus@a00 {
		#address-cells = <1>;
		#size-cells = <0>;
		#interrupt-cells = <1>;
		reg = <0xA00 0x80>, <0xAA0 0x20>;
		compatible = "aspeed,ast2600-i2cv2";
		aspeed,global-regs = <&i2c_global>;
		aspeed,enable-dma;
		clocks = <&io_clk AST2700_IO_CLK_APB>;
		resets = <&io_clk ASPEED_RESET_I2C>;
		interrupts-extended = <&intc2 9>;
		clock-frequency = <100000>;
		pinctrl-names = "default";
		pinctrl-0 = <&pinctrl_i2c9_default>;
		status = "disabled";
	};

	i2c10: i2c-bus@b00 {
		#address-cells = <1>;
		#size-cells = <0>;
		#interrupt-cells = <1>;
		reg = <0xB00 0x80>, <0xBA0 0x20>;
		compatible = "aspeed,ast2600-i2cv2";
		aspeed,global-regs = <&i2c_global>;
		aspeed,enable-dma;
		clocks = <&io_clk AST2700_IO_CLK_APB>;
		resets = <&io_clk ASPEED_RESET_I2C>;
		interrupts-extended = <&intc2 10>;
		clock-frequency = <100000>;
		pinctrl-names = "default";
		pinctrl-0 = <&pinctrl_i2c10_default>;
		status = "disabled";
	};

	i2c11: i2c-bus@c00 {
		#address-cells = <1>;
		#size-cells = <0>;
		#interrupt-cells = <1>;
		reg = <0xC00 0x80>, <0xCA0 0x20>;
		compatible = "aspeed,ast2600-i2cv2";
		aspeed,global-regs = <&i2c_global>;
		aspeed,enable-dma;
		clocks = <&io_clk AST2700_IO_CLK_APB>;
		resets = <&io_clk ASPEED_RESET_I2C>;
		interrupts-extended = <&intc2 11>;
		clock-frequency = <100000>;
		pinctrl-names = "default";
		pinctrl-0 = <&pinctrl_i2c11_default>;
		status = "disabled";
	};

	i2c12: i2c-bus@d00 {
		#address-cells = <1>;
		#size-cells = <0>;
		#interrupt-cells = <1>;
		reg = <0xD00 0x80>, <0xDA0 0x20>;
		compatible = "aspeed,ast2600-i2cv2";
		aspeed,global-regs = <&i2c_global>;
		aspeed,enable-dma;
		clocks = <&io_clk AST2700_IO_CLK_APB>;
		resets = <&io_clk ASPEED_RESET_I2C>;
		interrupts-extended = <&intc2 12>;
		clock-frequency = <100000>;
		pinctrl-names = "default";
		pinctrl-0 = <&pinctrl_i2c12_default>;
		status = "disabled";
	};

	i2c13: i2c-bus@e00 {
		#address-cells = <1>;
		#size-cells = <0>;
		#interrupt-cells = <1>;
		reg = <0xE00 0x80>, <0xEA0 0x20>;
		compatible = "aspeed,ast2600-i2cv2";
		aspeed,global-regs = <&i2c_global>;
		aspeed,enable-dma;
		clocks = <&io_clk AST2700_IO_CLK_APB>;
		resets = <&io_clk ASPEED_RESET_I2C>;
		interrupts-extended = <&intc2 13>;
		clock-frequency = <100000>;
		pinctrl-names = "default";
		pinctrl-0 = <&pinctrl_i2c13_default>;
		status = "disabled";
	};

	i2c14: i2c-bus@f00 {
		#address-cells = <1>;
		#size-cells = <0>;
		#interrupt-cells = <1>;
		reg = <0xF00 0x80>, <0xFA0 0x20>;
		compatible = "aspeed,ast2600-i2cv2";
		aspeed,global-regs = <&i2c_global>;
		aspeed,enable-dma;
		clocks = <&io_clk AST2700_IO_CLK_APB>;
		resets = <&io_clk ASPEED_RESET_I2C>;
		interrupts-extended = <&intc2 14>;
		clock-frequency = <100000>;
		pinctrl-names = "default";
		pinctrl-0 = <&pinctrl_i2c14_default>;
		status = "disabled";
	};

	i2c15: i2c-bus@1000 {
		#address-cells = <1>;
		#size-cells = <0>;
		#interrupt-cells = <1>;
		reg = <0x1000 0x80>, <0x10A0 0x20>;
		compatible = "aspeed,ast2600-i2cv2";
		aspeed,global-regs = <&i2c_global>;
		aspeed,enable-dma;
		clocks = <&io_clk AST2700_IO_CLK_APB>;
		resets = <&io_clk ASPEED_RESET_I2C>;
		interrupts-extended = <&intc2 15>;
		clock-frequency = <100000>;
		pinctrl-names = "default";
		pinctrl-0 = <&pinctrl_i2c15_default>;
		status = "disabled";
	};
};
